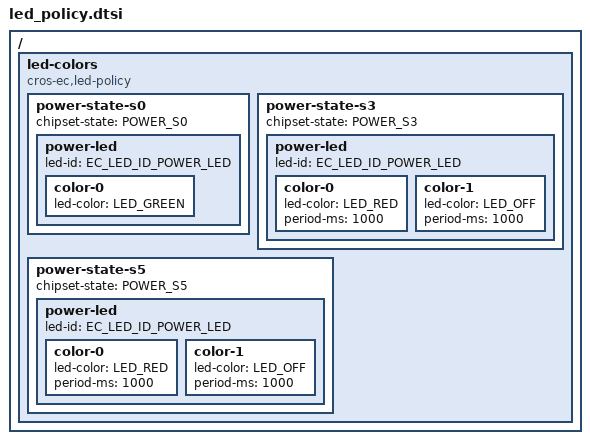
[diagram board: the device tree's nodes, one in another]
/ {
	led-colors {
		compatible = "cros-ec,led-policy";

		power-state-s0 {
			chipset-state = "POWER_S0";

			power-led {
				led-id = "EC_LED_ID_POWER_LED";

				color-0 {
					led-color = "LED_GREEN";
				};
			};
		};

		power-state-s3 {
			chipset-state = "POWER_S3";

			power-led {
				led-id = "EC_LED_ID_POWER_LED";

				color-0 {
					led-color = "LED_RED";
					period-ms = <1000>;
				};
				color-1 {
					led-color = "LED_OFF";
					period-ms = <1000>;
				};
			};
		};


		power-state-s5 {
			chipset-state = "POWER_S5";

			power-led {
				led-id = "EC_LED_ID_POWER_LED";

				color-0 {
					led-color = "LED_RED";
					period-ms = <1000>;
				};
				color-1 {
					led-color = "LED_OFF";
					period-ms = <1000>;
				};
			};
		};
	};
};
